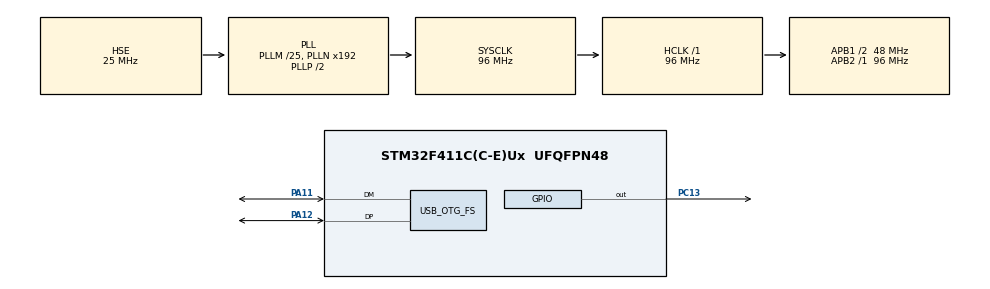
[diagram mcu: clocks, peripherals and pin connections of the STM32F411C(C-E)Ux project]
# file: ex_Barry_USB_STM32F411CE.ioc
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FREERTOS.Tasks01=defaultTask,0,128,StartDefaultTask,Default,NULL,Dynamic,NULL,NULL
FREERTOS.configUSE_NEWLIB_REENTRANT=1
Mcu.Family=STM32F4
Mcu.Name=STM32F411C(C-E)Ux
Mcu.Package=UFQFPN48
NVIC.OTG_FS_IRQn=true\:5\:0\:false\:false\:true\:true\:false\:true\:true
NVIC.PriorityGroup=NVIC_PRIORITYGROUP_4
NVIC.TIM4_IRQn=true\:15\:0\:false\:false\:true\:false\:false\:true\:true
NVIC.TimeBase=TIM4_IRQn
NVIC.TimeBaseIP=TIM4
PA11.Mode=Device_Only
PA11.Signal=USB_OTG_FS_DM
PA12.Mode=Device_Only
PA12.Signal=USB_OTG_FS_DP
PA13.Mode=Serial_Wire
PA13.Signal=SYS_JTMS-SWDIO
PA14.Mode=Serial_Wire
PA14.Signal=SYS_JTCK-SWCLK
PC13-ANTI_TAMP.Signal=GPIO_Output
PH0\ -\ OSC_IN.Mode=HSE-External-Oscillator
PH0\ -\ OSC_IN.Signal=RCC_OSC_IN
PH1\ -\ OSC_OUT.Mode=HSE-External-Oscillator
PH1\ -\ OSC_OUT.Signal=RCC_OSC_OUT
ProjectManager.HeapSize=0x200
ProjectManager.StackSize=0x400
ProjectManager.TargetToolchain=STM32CubeIDE
RCC.48MHZClocksFreq_Value=48000000
RCC.AHBFreq_Value=96000000
RCC.APB1CLKDivider=RCC_HCLK_DIV2
RCC.APB1Freq_Value=48000000
RCC.APB1TimFreq_Value=96000000
RCC.APB2Freq_Value=96000000
RCC.APB2TimFreq_Value=96000000
RCC.CortexFreq_Value=96000000
RCC.HCLKFreq_Value=96000000
RCC.HSE_VALUE=25000000
RCC.HSI_VALUE=16000000
RCC.LSE_VALUE=32768
RCC.PLLM=25
RCC.SYSCLKFreq_VALUE=96000000
RCC.SYSCLKSource=RCC_SYSCLKSOURCE_PLLCLK
RCC.VCOOutputFreq_Value=192000000
USB_DEVICE.CLASS_NAME_FS=CDC
USB_DEVICE.VirtualMode=Cdc
USB_DEVICE.VirtualModeFS=Cdc_FS
USB_OTG_FS.VirtualMode=Device_Only
VP_FREERTOS_VS_CMSIS_V1.Mode=CMSIS_V1
VP_SYS_VS_tim4.Mode=TIM4
VP_USB_DEVICE_VS_USB_DEVICE_CDC_FS.Mode=CDC_FS
board=custom

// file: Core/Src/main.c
/* USER CODE BEGIN Header */
/**
  ******************************************************************************
  * @file           : main.c
  * @brief          : Main program body
  ******************************************************************************
  * @attention
  *
  * Copyright (c) 2025 STMicroelectronics.
  * All rights reserved.
  *
  * This software is licensed under terms that can be found in the LICENSE file
  * in the root directory of this software component.
  * If no LICENSE file comes with this software, it is provided AS-IS.
  *
  ******************************************************************************
  */
/* USER CODE END Header */
#include "main.h"
#include "cmsis_os.h"
#include "usb_device.h"

/* USER CODE BEGIN Includes */
#include "lab_examples.h"
#include "usbd_cdc_if.h"
#include "usbd_cdc.h"
#include "semphr.h"
#include <stdio.h>
#include <string.h>
/* USER CODE END Includes */

osThreadId defaultTaskHandle;
/* USER CODE BEGIN PV */
static SemaphoreHandle_t usbWriteMutex;
static uint8_t usbTxBuffer[256];
/* USER CODE END PV */

void SystemClock_Config(void);
static void MX_GPIO_Init(void);
void StartDefaultTask(void const * argument);

int main(void)
{

  /* MCU Configuration--------------------------------------------------------*/

  /* Reset of all peripherals, Initializes the Flash interface and the Systick. */
  HAL_Init();

  /* Configure the system clock */
  SystemClock_Config();

  /* Initialize all configured peripherals */
  MX_GPIO_Init();

  /* Create the thread(s) */
  /* definition and creation of defaultTask */
  osThreadDef(defaultTask, StartDefaultTask, osPriorityNormal, 0, 128);
  defaultTaskHandle = osThreadCreate(osThread(defaultTask), NULL);

  /* Start scheduler */
  osKernelStart();

  /* We should never get here as control is now taken by the scheduler */

  /* Infinite loop */
  while (1)
  {

  }
}

void SystemClock_Config(void)
{
  RCC_OscInitTypeDef RCC_OscInitStruct = {0};
  RCC_ClkInitTypeDef RCC_ClkInitStruct = {0};

  /** Configure the main internal regulator output voltage
  */
  __HAL_RCC_PWR_CLK_ENABLE();
  __HAL_PWR_VOLTAGESCALING_CONFIG(PWR_REGULATOR_VOLTAGE_SCALE1);

  /** Initializes the RCC Oscillators according to the specified parameters
  * in the RCC_OscInitTypeDef structure.
  */
  RCC_OscInitStruct.OscillatorType = RCC_OSCILLATORTYPE_HSE;
  RCC_OscInitStruct.HSEState = RCC_HSE_ON;
  RCC_OscInitStruct.PLL.PLLState = RCC_PLL_ON;
  RCC_OscInitStruct.PLL.PLLSource = RCC_PLLSOURCE_HSE;
  RCC_OscInitStruct.PLL.PLLM = 25;
  RCC_OscInitStruct.PLL.PLLN = 192;
  RCC_OscInitStruct.PLL.PLLP = RCC_PLLP_DIV2;
  RCC_OscInitStruct.PLL.PLLQ = 4;
  if (HAL_RCC_OscConfig(&RCC_OscInitStruct) != HAL_OK)
  {
    Error_Handler();
  }

  /** Initializes the CPU, AHB and APB buses clocks
  */
  RCC_ClkInitStruct.ClockType = RCC_CLOCKTYPE_HCLK|RCC_CLOCKTYPE_SYSCLK
                              |RCC_CLOCKTYPE_PCLK1|RCC_CLOCKTYPE_PCLK2;
  RCC_ClkInitStruct.SYSCLKSource = RCC_SYSCLKSOURCE_PLLCLK;
  RCC_ClkInitStruct.AHBCLKDivider = RCC_SYSCLK_DIV1;
  RCC_ClkInitStruct.APB1CLKDivider = RCC_HCLK_DIV2;
  RCC_ClkInitStruct.APB2CLKDivider = RCC_HCLK_DIV1;

  if (HAL_RCC_ClockConfig(&RCC_ClkInitStruct, FLASH_LATENCY_3) != HAL_OK)
  {
    Error_Handler();
  }
}

static void MX_GPIO_Init(void)
{
  GPIO_InitTypeDef GPIO_InitStruct = {0};

  /* GPIO Ports Clock Enable */
  __HAL_RCC_GPIOC_CLK_ENABLE();
  __HAL_RCC_GPIOH_CLK_ENABLE();
  __HAL_RCC_GPIOA_CLK_ENABLE();

  /*Configure GPIO pin Output Level */
  HAL_GPIO_WritePin(GPIOC, GPIO_PIN_13, GPIO_PIN_RESET);

  /*Configure GPIO pin : PC13 */
  GPIO_InitStruct.Pin = GPIO_PIN_13;
  GPIO_InitStruct.Mode = GPIO_MODE_OUTPUT_PP;
  GPIO_InitStruct.Pull = GPIO_NOPULL;
  GPIO_InitStruct.Speed = GPIO_SPEED_FREQ_LOW;
  HAL_GPIO_Init(GPIOC, &GPIO_InitStruct);

}

/* USER CODE BEGIN 4 */
// Redirect printf() to USB Virtual COM Port
int _write(int file, char *ptr, int len)
{
  extern USBD_HandleTypeDef hUsbDeviceFS;
  USBD_CDC_HandleTypeDef *cdc;
  int sent = 0;
  (void)file;

  if (len <= 0 || usbWriteMutex == NULL) return len;
  if (xSemaphoreTake(usbWriteMutex, portMAX_DELAY) != pdTRUE) return len;
  while (sent < len) {
    uint32_t start = HAL_GetTick();
    uint16_t chunk = (uint16_t)((len - sent) > sizeof(usbTxBuffer)
                              ? sizeof(usbTxBuffer) : (len - sent));
    if (hUsbDeviceFS.dev_state != USBD_STATE_CONFIGURED ||
        hUsbDeviceFS.pClassData == NULL) break;

    cdc = (USBD_CDC_HandleTypeDef *)hUsbDeviceFS.pClassData;
    while (cdc->TxState != 0) {
      if (HAL_GetTick() - start > 100) goto done;
      osDelay(1);
      cdc = (USBD_CDC_HandleTypeDef *)hUsbDeviceFS.pClassData;
      if (cdc == NULL) goto done;
    }

    memcpy(usbTxBuffer, ptr + sent, chunk);
    if (CDC_Transmit_FS(usbTxBuffer, chunk) != USBD_OK) break;
    while (cdc->TxState != 0) {
      if (HAL_GetTick() - start > 100) goto done;
      osDelay(1);
      cdc = (USBD_CDC_HandleTypeDef *)hUsbDeviceFS.pClassData;
      if (cdc == NULL) goto done;
    }
    sent += chunk;
  }
done:
  xSemaphoreGive(usbWriteMutex);
  return len;
}
/* USER CODE END 4 */

void StartDefaultTask(void const * argument)
{
  usbWriteMutex = xSemaphoreCreateMutex();
  /* init code for USB_DEVICE */
  MX_USB_DEVICE_Init();
  /* USER CODE BEGIN 5 */
  osDelay(1000); /* Allow the USB CDC port to enumerate before printing. */
  LabExamples_Start();
  vTaskDelete(NULL);
  /* USER CODE END 5 */
}

void HAL_TIM_PeriodElapsedCallback(TIM_HandleTypeDef *htim)
{
  if (htim->Instance == TIM4)
  {
    HAL_IncTick();
  }
}

void Error_Handler(void)
{
  __disable_irq();
  while (1)
  {
  }
}
